# PCIE1_CORE_DBN_CFG_PCIE_CORE register map
Vendor: Texas Instruments
Registers are 32-bit, read-write, reset 0x0 unless marked. A register's access mark holds for its fields unless they carry their own. Offsets are as the file gives them; [hi:lo] are bit positions; {n}, {i} and the like mark numbered series; 'fields as' and 'values as' point back to an identical list.

## PCIE1_CORE_DBN_CFG_PCIE_CORE (part 6 of 7)
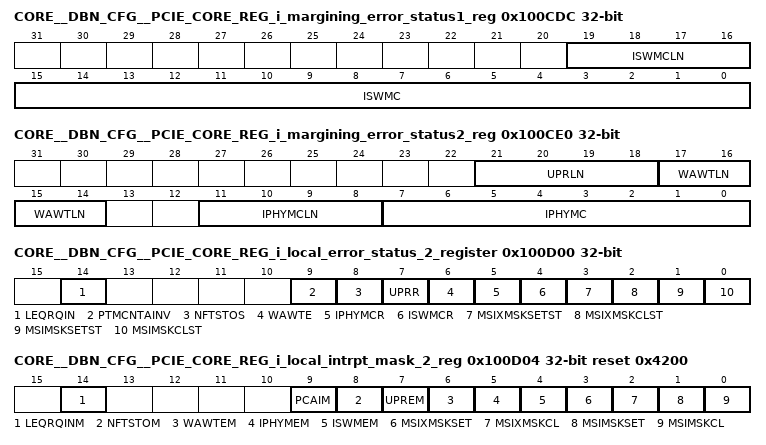
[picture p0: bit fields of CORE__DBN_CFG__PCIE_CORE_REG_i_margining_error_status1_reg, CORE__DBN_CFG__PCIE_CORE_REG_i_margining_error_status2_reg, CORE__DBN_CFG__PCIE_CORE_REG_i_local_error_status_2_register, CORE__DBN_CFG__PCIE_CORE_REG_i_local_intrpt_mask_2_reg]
0x100CDC CORE__DBN_CFG__PCIE_CORE_REG_i_margining_error_status1_reg ro — The Lane Margining at Receiver SW Error Status fields are implemented in this Register.
  [19:16] ISWMCLN — This field reports the Lane Number for which the Invalid command was received. 0000: Lane 0. 0001: Lane 1. and so on.. This register is valid only when Bit-4, Invalid SW Margining Command Received, of the i_local_error_status_2_register is set. Bit-4 of the i_local_error_status_2_register has to be cleared by local firmware before another error can be logged in this field. .
  [15:0] ISWMC — When the Controller receives an Invalid Margining Command from SW in its configuration register, the 16-bit command is logged in this register for debug. Only the first Error is logged in this register. This register is valid only when Bit-4, Invalid SW Margining Command Received, of the i_local_error_status_2_register is set. Bit-4 of the i_local_error_status_2_register has to be cleared by local firmware before another error can be logged in this field. .
0x100CE0 CORE__DBN_CFG__PCIE_CORE_REG_i_margining_error_status2_reg ro — The Lane Margining at Receiver PHY Error Status fields are implemented in this Register.
  [21:18] UPRLN — This field reports the Lane Number for which the Controller received an unexpected PHY Response for Lane Margining. Unexpected PHY Response is detected by Controller if PHY writes to the Margin Status or the Margin NAK bits of RX Margin Status 0 Register when no change in Start Margin or Margin Offset issued by Controller or after the Write Ack Wait Timeout. 0000: Lane 0. 0001: Lane 1. and so on.. This field is valid only when Bit-7, Unexpected PHY Response Received, of the i_local_error_status_2_register is set. Bit-7 of the i_local_error_status_2_register has to be cleared by local firmware before another error can be logged in this field. .
  [17:14] WAWTLN — This field reports the Lane Number for which the Controller detected a 10ms timeout. 0000: Lane 0. 0001: Lane 1. and so on.. This field is valid only when Bit-6, Write Ack Wait Timeout Error, of the i_local_error_status_2_register is set. Bit-6 of the i_local_error_status_2_register has to be cleared by local firmware before another error can be logged in this field. .
  [11:8] IPHYMCLN — This field reports the Lane Number for which the Invalid command was received. 0000: Lane 0. 0001: Lane 1. and so on.. This field is valid only when Bit-5, Invalid PHY Margining Command Received, of the i_local_error_status_2_register is set. Bit-5 of the i_local_error_status_2_register has to be cleared by local firmware before another error can be logged in this field. .
  [7:0] IPHYMC — When the Controller receives an Invalid Margining Command from PHY over PIPE Interface, the 8-bit PIPE command is logged in this register for debug. Only the first Error is logged in this register. This field is valid only when Bit-5, Invalid PHY Margining Command Received, of the i_local_error_status_2_register is set. Bit-5 of the i_local_error_status_2_register has to be cleared by local firmware before another error can be logged in this field. .
0x100D00 CORE__DBN_CFG__PCIE_CORE_REG_i_local_error_status_2_register access not given — This is an extension of the Local Error and Status Register. This register contains the status of the various events, errors and abnormal conditions in the Controller. Any of the status bits can be reset by writing a 1 into the bit position. Unless masked by the setting of the Local Interrupt Mask 2 Register, the occurrence of any of these conditions causes the Controller to activate the LOCAL_INTERRUPT output.
  [14] LEQRQIN — EP Mode: Indicates that the Controller hardware detected a problem with equalization and automatically requested for equalization redo at the end of the equalization. Controller checks for problems in Recovery.Rcvr.Lock state by comparing the Tx Coefficients agreed at end of Eq Phase2 with the Tx Coefficients received in TS1s in Recovery.Rcvr.Lock state at the end of equalization. Any mismatch is detected and the Request Equalization bit is set in Recovery.Rcvg.Cfg. This bit is set for both 8GT/s and 16GT/s equalization requests. [i] The Link Eq Request 8GT/s bit-5 in Link Status 2 Register will be set for 8GT/s Eq Request. [ii] The Link Eq Request 16.0 GT/s, bit-4 in 16.0 GT/s Status Register will be set for 16GT/s Eq Request. RC Mode: Indicates that the Controller received Equalization Request from downstream component. This bit is set for both 8GT/s and 16GT/s equalization requests. [i] The Link Eq Request 8GT/s bit-5 in Link Status 2 Register will be set for 8GT/s Eq Request. [ii] The Link Eq Request 16.0 GT/s, bit-4 in 16.0 GT/s Status Register will be set for 16GT/s Eq Request. (access R/W1TC)
  [9] PTMCNTAINV — This status bit indicates that the Controller automatically invalidated PTM Context because of PCIe Link exit from L0 State. (access R/W1TC)
  [8] NFTSTOS — This status bit indicates that a NFTS Timeout occured. This could occur if the PHY failed to achieve lock on the receive data before the NFTS Timeout during Rx_L0s.FTS state. Local Firmware should consider increasing the advertized NFTS values if this event occurs. (access R/W1TC)
  [7] UPRR — This bit indicates that the Controller received an unexpected PHY Response for Lane Margining. The lane on which this error was detected is captured in bits 21:18 of the margining_error_status2_reg register. Unexpected PHY Response is detected by Controller if PHY writes to the Margin Status or the Margin NAK bits of the MAC RX Margin Status 0 Register when no change in Start Margin or Margin Offset issued by Controller or after the Write Ack Wait Timeout. This bit is set upon receiving the first Error. Local firmware must clear this bit by writing a 1 to this bit before another error can be logged in the margining_error_status2_reg register. (access R/W1TC)
  [6] WAWTE — This bit indicates that the Controller detected a 10ms timeout while waiting for Write Ack Lane Margining response from a PHY. The lane on which this timeout was detected is captured in bits 17:14 of the margining_error_status2_reg register. This bit is set upon receiving the first Error. Local firmware must clear this bit by writing a 1 to this bit before another error can be logged in the margining_error_status2_reg register. (access R/W1TC)
  [5] IPHYMCR — This bit validates the 8-bit command stored in bits [7:0] and the Lane Number stored in bits [11:8] of the margining_error_status1_reg register. This bit is set upon receiving the first Error. Local firmware must clear this bit by writing a 1 to this bit before another error can be logged in the margining_error_status1_reg register. (access R/W1TC)
  [4] ISWMCR — This bit validates the 16-bit command stored in bits [15:0] and the Lane Number stored in bits [19:16] of the margining_error_status1_reg register. This bit is set upon receiving the first Error. Local firmware must clear this bit by writing a 1 to this bit before another error can be logged in the margining_error_status1_reg register. (access R/W1TC)
  [3] MSIXMSKSETST — This status bit indicates that the MSIX Function Mask of any function, PF or VF, was programmed or configured from 0 to 1 by Local Firmware Or Host SW. This bit is set only when the MSIX Function Mask Change Enhanced Interrupt Enable bit is set by the User in debug_mux_control_2_reg. When this status bit is set, the Controller asserts LOCAL_INTERRUPT if not masked in local_intrpt_mask_2_reg . Note that this is a Read Only Status bit. The MSIX Function Mask Clear status per-function is captured in the msix_function_mask_set_status_register. Firmware has to clear the per-function bits in msix_function_mask_set_status_register in order to clear this status bit and to deassert LOCAL_INTERRUPT. (access R/W1TC)
  [2] MSIXMSKCLST — This status bit indicates that the MSIX Function Mask of any function, PF or VF, was programmed or configured from 1 to 0 by Local Firmware Or Host SW. This bit is set only when the MSIX Function Mask Change Enhanced Interrupt Enable bit is set by the User in debug_mux_control_2_reg. When this status bit is set, the Controller asserts LOCAL_INTERRUPT if not masked in local_intrpt_mask_2_reg . Note that this is a Read Only Status bit. The MSIX Function Mask Clear status per-function is captured in the msix_function_mask_cleared_status_register. Firmware has to clear the per-function bits in msix_function_mask_cleared_status_register in order to clear this status bit and to deassert LOCAL_INTERRUPT. (access R/W1TC)
  [1] MSIMSKSETST — This status bit indicates that One or More bits of MSI Mask of any function, PF or VF, was programmed or configured from 0 to 1 by Local Firmware Or Host SW. This bit is set only when the MSI Mask Change Enhanced Interrupt Enable bit is set by the User in debug_mux_control_2_reg. When this status bit is set, the Controller asserts LOCAL_INTERRUPT if not masked in local_intrpt_mask_2_reg . Note that this is a Read Only Status bit. The MSI Mask Clear status per-function is captured in the msi_mask_set_status_register. Firmware has to clear the per-function bits in msi_mask_set_status_register in order to clear this status bit and to deassert LOCAL_INTERRUPT. (access R/W1TC)
  [0] MSIMSKCLST — This status bit indicates that One or More bits of MSI Mask of any function, PF or VF, was programmed or configured from 1 to 0 by Local Firmware Or Host SW. This bit is set only when the MSI Mask Change Enhanced Interrupt Enable bit is set by the User in debug_mux_control_2_reg. When this status bit is set, the Controller asserts LOCAL_INTERRUPT if not masked in local_intrpt_mask_2_reg . Note that this is a Read Only Status bit. The MSI Mask Clear status per-function is captured in the msi_mask_cleared_status_register. Firmware has to clear the per-function bits in msi_mask_cleared_status_register in order to clear this status bit and to deassert LOCAL_INTERRUPT. (access R/W1TC)
0x100D04 CORE__DBN_CFG__PCIE_CORE_REG_i_local_intrpt_mask_2_reg reset 0x4200 — This is an extension of the Local Interrupt Mask Register. This register contains a mask bit for each interrupting condition in local_error_status_2_register. Setting the bit to 1 prevents the corresponding condition in the Local Error Status 2 Register from activating the LOCAL_INTERRUPT output.
  [14] LEQRQINM — Mask for Link Equalization Request Interrupt.
  [9] PCAIM — Mask for PTM Context Auto Invalidated event.
  [8] NFTSTOM — Mask for NFTS Timeout.
  [7] UPREM — Unexpected PHY Response is detected by Controller if PHY writes to the Margin Status or the Margin NAK bits of RX Margin Status 0 Register when no change in Start Margin or Margin Offset issued by Controller or after the Write Ack Wait Timeout This bit can be used to Mask asserting the LOCAL_INTERRUPT output upon this error. 1: Error is masked. 0: Error is not masked.
  [6] WAWTEM — When a WriteCommitted command is issued by the Controller, the PHY must respond with a Write_Ack within 10ms on the PIPE Message Bus Interface. However, if the Write_Ack is not received within 10ms, the Controller reports Timeout and stops waiting for the write_ack. This bit can be used to Mask asserting the LOCAL_INTERRUPT output upon this 10ms timeout. 1: Error is masked. 0: Error is not masked.
  [5] IPHYMEM — When the Controller receives a Margining Command from PHY over the PIPE Interface, it checks if the command is valid. The error status is logged in local_error_status_2_register. This bit can be used to Mask asserting the LOCAL_INTERRUPT output when the Invalid PHY Margining Error Status is set. 1: Error is masked. 0: Error is not masked.
  [4] ISWMEM — When the Controller receives a Margining Command from SW in its configuration register, it checks if the command is valid. The error status is logged in local_error_status_2_register. This bit can be used to Mask asserting the LOCAL_INTERRUPT output when the Invalid SW Margining Error Status is set. 1: Error is masked. 0: Error is not masked. .
  [3] MSIXMSKSET — Mask for MSIX Function Mask Cleared Status.
  [2] MSIXMSKCL — Mask for MSIX Function Mask Set Status.
  [1] MSIMSKSET — Mask for MSI Mask Set Status.
  [0] MSIMSKCL — Mask for MSI Mask Cleared Status.
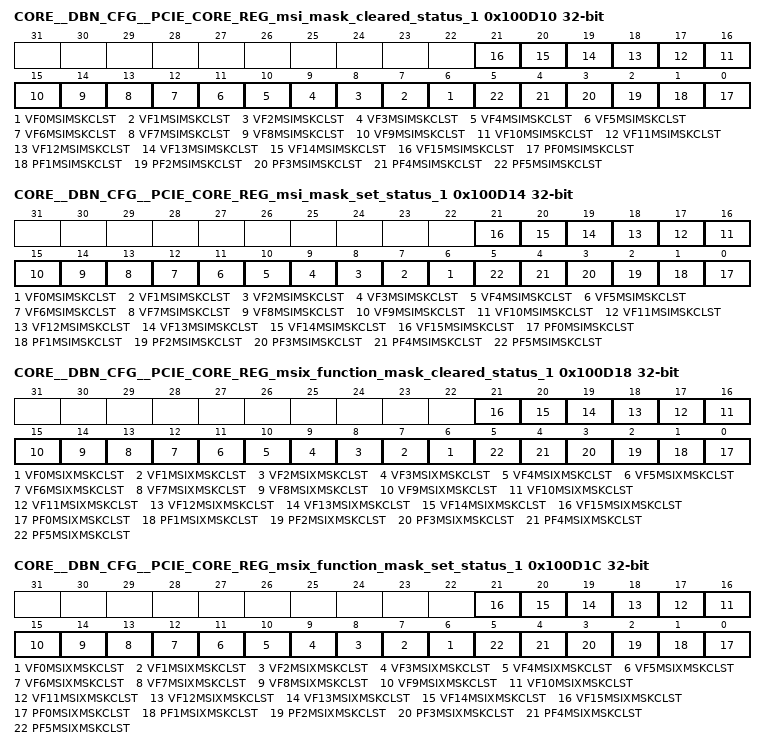
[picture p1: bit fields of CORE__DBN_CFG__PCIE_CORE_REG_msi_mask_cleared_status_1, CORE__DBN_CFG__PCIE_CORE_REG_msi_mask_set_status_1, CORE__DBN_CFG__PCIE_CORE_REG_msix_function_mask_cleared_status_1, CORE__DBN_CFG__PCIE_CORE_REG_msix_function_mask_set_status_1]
0x100D10 CORE__DBN_CFG__PCIE_CORE_REG_msi_mask_cleared_status_1 access not given — This status register has one bit per function. Each function has a 32-bit MSI Mask. If any bit in the function's MSI Mask register is configured from 1 to 0, then the corresponding function's status bit in this register is set. Local Firmware needs to clear this register by writing a 1.
  [n+6] VF{n}MSIMSKCLST (n=0..15) — Each VF has a 32-bit MSI Mask. This status bit is set when any of the 32-bits in VF{n} MSI Mask is programmed or configured from 1 to 0 by Local Firmware Or Host SW. This bit is set only when the MSI Mask Change Enhanced Interrupt Enable bit is set by the User in debug_mux_control_2_reg. When this status bit is set, the Controller asserts LOCAL_INTERRUPT if not masked in local_intrpt_mask_2_reg . Firmware has to clear this bit in order to deassert LOCAL_INTERRUPT. (access R/W1TC)
  [n] PF{n}MSIMSKCLST (n=0..5) — Each PF has a 32-bit MSI Mask. This status bit is set when any of the 32-bits in PF{n} MSI Mask is programmed or configured from 1 to 0 by Local Firmware Or Host SW. This bit is set only when the MSI Mask Change Enhanced Interrupt Enable bit is set by the User in debug_mux_control_2_reg. When this status bit is set, the Controller asserts LOCAL_INTERRUPT if not masked in local_intrpt_mask_2_reg . Firmware has to clear this bit in order to deassert LOCAL_INTERRUPT. (access R/W1TC)
0x100D14 CORE__DBN_CFG__PCIE_CORE_REG_msi_mask_set_status_1 access not given — This status register has one bit per function. Each function has a 32-bit MSI Mask. If any bit in the function's MSI Mask register is configured from 0 to 1, then the corresponding function's status bit in this register is set. Local Firmware needs to clear this register by writing a 1.
  [n+6] VF{n}MSIMSKCLST (n=0..15) — Each VF has a 32-bit MSI Mask. This status bit is set when any of the 32-bits in VF{n} MSI Mask is programmed or configured from 0 to 1 by Local Firmware Or Host SW. This bit is set only when the MSI Mask Change Enhanced Interrupt Enable bit is set by the User in debug_mux_control_2_reg. When this status bit is set, the Controller asserts LOCAL_INTERRUPT if not masked in local_intrpt_mask_2_reg . Firmware has to clear this bit in order to deassert LOCAL_INTERRUPT. (access R/W1TC)
  [n] PF{n}MSIMSKCLST (n=0..5) — Each PF has a 32-bit MSI Mask. This status bit is set when any of the 32-bits in PF{n} MSI Mask is programmed or configured from 0 to 1 by Local Firmware Or Host SW. This bit is set only when the MSI Mask Change Enhanced Interrupt Enable bit is set by the User in debug_mux_control_2_reg. When this status bit is set, the Controller asserts LOCAL_INTERRUPT if not masked in local_intrpt_mask_2_reg . Firmware has to clear this bit in order to deassert LOCAL_INTERRUPT. (access R/W1TC)
0x100D18 CORE__DBN_CFG__PCIE_CORE_REG_msix_function_mask_cleared_status_1 access not given — This status register has one bit per function. Each function has a 1-bit MSIX Function Mask. If the function's MSIX Function Mask register is configured from 1 to 0, then the corresponding function's status bit in this register is set. Local Firmware needs to clear this register by writing a 1.
  [n+6] VF{n}MSIXMSKCLST (n=0..15) — Each VF has a 1-bit MSIX Function Mask. This status bit is set when the VF{n} MSIX Function Mask is programmed or configured from 1 to 0 by Local Firmware Or Host SW. This bit is set only when the MSIX Function Mask Change Enhanced Interrupt Enable bit is set by the User in debug_mux_control_2_reg. When this status bit is set, the Controller asserts LOCAL_INTERRUPT if not masked in local_intrpt_mask_2_reg . Firmware has to clear this bit in order to deassert LOCAL_INTERRUPT. (access R/W1TC)
  [n] PF{n}MSIXMSKCLST (n=0..5) — Each PF has a 1-bit MSIX Function Mask. This status bit is set when the PF{n} MSIX Function Mask is programmed or configured from 1 to 0 by Local Firmware Or Host SW. This bit is set only when the MSIX Function Mask Change Enhanced Interrupt Enable bit is set by the User in debug_mux_control_2_reg. When this status bit is set, the Controller asserts LOCAL_INTERRUPT if not masked in local_intrpt_mask_2_reg . Firmware has to clear this bit in order to deassert LOCAL_INTERRUPT. (access R/W1TC)
0x100D1C CORE__DBN_CFG__PCIE_CORE_REG_msix_function_mask_set_status_1 access not given — This status register has one bit per function. Each function has a 1-bit MSIX Function Mask. If the function's MSIX Function Mask register is configured from 0 to 1, then the corresponding function's status bit in this register is set. Local Firmware needs to clear this register by writing a 1.
  [n+6] VF{n}MSIXMSKCLST (n=0..15) — Each VF has a 1-bit MSIX Function Mask. This status bit is set when the VF{n} MSIX Function Mask is programmed or configured from 0 to 1 by Local Firmware Or Host SW. This bit is set only when the MSIX Function Mask Change Enhanced Interrupt Enable bit is set by the User in debug_mux_control_2_reg. When this status bit is set, the Controller asserts LOCAL_INTERRUPT if not masked in local_intrpt_mask_2_reg . Firmware has to clear this bit in order to deassert LOCAL_INTERRUPT. (access R/W1TC)
  [n] PF{n}MSIXMSKCLST (n=0..5) — Each PF has a 1-bit MSIX Function Mask. This status bit is set when the PF{n} MSIX Function Mask is programmed or configured from 0 to 1 by Local Firmware Or Host SW. This bit is set only when the MSIX Function Mask Change Enhanced Interrupt Enable bit is set by the User in debug_mux_control_2_reg. When this status bit is set, the Controller asserts LOCAL_INTERRUPT if not masked in local_intrpt_mask_2_reg . Firmware has to clear this bit in order to deassert LOCAL_INTERRUPT. (access R/W1TC)
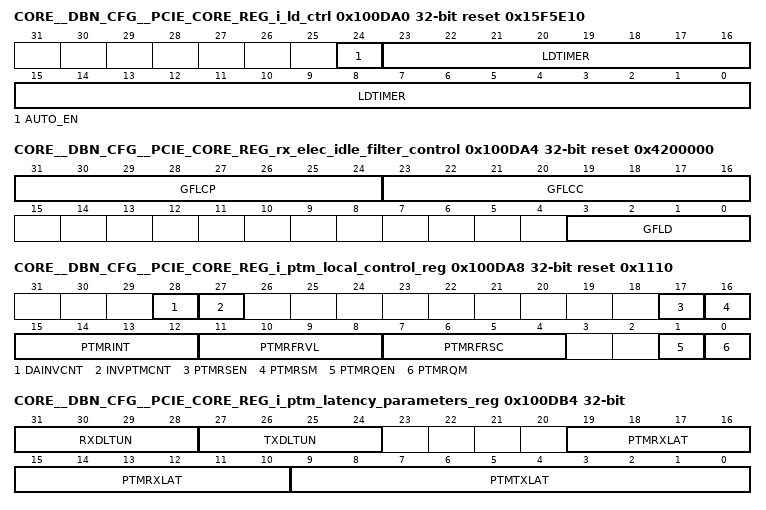
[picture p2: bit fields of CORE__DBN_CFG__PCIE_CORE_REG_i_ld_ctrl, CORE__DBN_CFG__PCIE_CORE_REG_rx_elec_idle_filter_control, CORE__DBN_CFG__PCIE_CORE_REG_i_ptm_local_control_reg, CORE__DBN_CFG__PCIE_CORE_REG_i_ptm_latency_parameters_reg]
0x100DA0 CORE__DBN_CFG__PCIE_CORE_REG_i_ld_ctrl reset 0x15F5E10 — This register is for the control of Link Down Indication Auto Reset behavior
  [24] AUTO_EN — This bit when set indicates that the link down indication auto reset is enabled
  [23:0] LDTIMER — This is a counter timeout value which triggers the internal logic to reset the link down indication bit in the AXI Configuration registers
0x100DA4 CORE__DBN_CFG__PCIE_CORE_REG_rx_elec_idle_filter_control reset 0x4200000 — This register controls the behavior of glitch filter on the pipe rx Electrical Idle signal from the PHY/PCS. Adjustment of this register is not required for normal operations.
  [31:24] GFLCP — This controls the glitch filter on PM Clock domain. This counter indicates the number of PM Clocks the glitch will be filtered out. The total delay of the glitch filter is calculated as [PM Clock Period * Number of PM Clocks] this delay should be same or close enough for both Core Clock[GFLCC] and PM Clock[GFLCP]
  [23:16] GFLCC — This controls the glitch filter on CORE Clock domain. This counter indicates the number of CORE Clocks the glitch will be filtered out. The total delay of the glitch filter is calculated as [CORE Clock Period * Number of CORE Clocks] this delay should be same or close enough for both CORE Clock[GFLCC] and PM Clock[GFLCP]
  [3:0] GFLD — By default controller enables glitch filter on all lanes. Setting this bit to one makes the controller to disable the glitch filter on that corresponding lanes in which the bit is set. When all bits are set to one the Glitch filter is completely bypassed, When any bit is zero glitch filter is enabled, and de-glitching is done only on the lanes that are set to zero
0x100DA8 CORE__DBN_CFG__PCIE_CORE_REG_i_ptm_local_control_reg access per field reset 0x1110 — The register bits to Control PTM operation are implemented in this Register.
  [28] DAINVCNT rw — By default, the Controller automatically invalidates PTM Context when the LTSSM exits L0 state. Client may disable this by writing a 1 to this register.
  [27] INVPTMCNT wo — Client Firmware may write a 1 to this bit in order to reset the PTM Context. This is a write-only bit. Controller internally clears this bit. Read from this bit returns 0. EP Mode: Resets the PTM Request State Machine. PTM Context is Cleared. RP Mode: Resets the PTM Response State Machine. PTM Context is Cleared.
  [17] PTMRSEN rw — EP Mode: Reserved RP Mode: This bit enables Controller [RP] to respond to the received PTM Requests. PTM Response/PTM ResponseD is determined by the PTM Response Mode bit. 1 : Controller automatically responds with Response/ResponseD messages. 0 : Controller does not respond for PTM Requests. [PTM Feature is Bypassed.]
  [16] PTMRSM rw — EP Mode: Reserved. RP Mode: This bit is used to control the number of PTM dialogs used during each PTM Master Time Request. 1 : Two Dialog Mode - Each PTM Context will have Response followed by ResponseD. Example: Dialog0: Request -> Response. Dialog1: Request -> ResponseD Dialog2: Request -> Response Dialog3: Request -> ResponseD 0 : Continuous Dialog Mode - Each PTM Context will have Only ResponseD. Example: Dialog0: Request -> Response. Dialog1: Request -> ResponseD Dialog2: Request -> ResponseD Dialog3: Request -> ResponseD
  [15:12] PTMRINT rw — EP Mode: In Single,Periodic Request Mode, this field is used to control the time interval [in us] between PTM Requests within a PTM Context. This represents the time the Requester State Machine waits in the WAIT_1US_STATE. 0001 - 1 0010 - 2 0011 - 3 0100 - 4 0101 - 5 0110 - 6 0111 - 7 1000 - 8 1001 - 9 .. 1111 - 15 This value is in [us]. RP Mode: Reserved.
  [11:8] PTMRFRVL rw — EP Mode: In Periodic Request Mode, this field is used to control the time interval [value] between successive PTM Context Refresh. This represents the time the Requester State Machine waits in the VALID_PTM_CONTEXT_STATE. 0001 - 1 0010 - 2 0011 - 3 0100 - 4 0101 - 5 0110 - 6 0111 - 7 1000 - 8 1001 - 9 1010 - 1111 Reserved This value is multiplied with the scale to determine the PTM Request Time Interval. RP Mode: Reserved.
  [7:4] PTMRFRSC rw — EP Mode: In Periodic Request Mode, this field is used to control the time interval [scale] between successive PTM Context Refresh. This represents the time the Requester State Machine waits in the VALID_PTM_CONTEXT_STATE. 0000 - 1 us 0001 - 10 us 0010 - 100 us 0011 - 1 ms 0100 - 10 ms 0101 - 100 ms 0110 - 1 s 0111 - 10 s 1000 - 100 s 1001 - 1111 - Reserved RP Mode: Reserved.
  [1] PTMRQEN rw — EP Mode: This enables Endpoint to request for PTM Master Time. 1 : PTM Requests are Enabled. In Single Request Mode, this bit is used to trigger PTM dialog to obtain PTM Master time exactly once. This bit is auto-cleared after the PTM Master time is obtained. In Periodic Request Mode, this bit enables periodic requests for PTM Master Time. This bit remains set till it is cleared by the EP local firmware. 0 : PTM Requests are Disabled. [PTM Feature is Bypassed.] User may disable PTM requests in the Controller and, if required, generate requests from Client Master Interface. RP Mode: Reserved.
  [0] PTMRQM rw — EP Mode: This bit controls the pattern of PTM Requests issued by the Endpoint. 0: Single Request Mode. 1: Periodic Request Mode. In Single Request Mode, Endpoint initiates one or two PTM Dialogs till the PTM Master Time is obtained. In Periodic Request Mode, Endpoint initiates PTM Dialogs and obtains PTM Master at periodic intervals. The period is programmable. RP Mode: Reserved.
0x100DAC CORE__DBN_CFG__PCIE_CORE_REG_i_ptm_local_status_reg ro — The status of PTM Dialog is reflected in this Register.
  [3:0] PTMCNST — Reflects the current status of the PTM Context. In EP Mode: 0000 - Invalid PTM Context 0001 - Dialog 1 PTM Request Sent 0011 - Dialog 1 PTM Response Received 0111 - Dialog 2 PTM Request Sent 1111 - Dialog 2 PTM ResponseD Received and PTM Context Valid In RP Mode: 0000 - Invalid PTM Context 0001 - Dialog 1 PTM Request Received 0011 - Dialog 1 PTM Response Sent 0111 - Dialog 2 PTM Request Received 1111 - Dialog 2 PTM ResponseD Sent and PTM Context Valid
0x100DB0 CORE__DBN_CFG__PCIE_CORE_REG_i_ptm_latency_parameters_index_reg — The latency parameters of the PHY may be different at different speeds of operation. Hence, the Controller implements multiple instances of the PTM Latency Parameters Register, one instance for each speed of operation. This register is used to select the speed prior to programming the speed-specific delay parameter registers.
  [3:0] PTMLATIN — This is used by FW to select the speed for which the Latency parameters are to be programmed. FW is required to set this to each of the supported speeds and program the corresponding latency parameters in the PTM Latency Parameters Register. 0000 - Gen1 Speed Select 0001 - Gen2 Speed Select 0010 - Gen3 Speed Select 0011 - Gen4 Speed Select Others - Reserved
0x100DB4 CORE__DBN_CFG__PCIE_CORE_REG_i_ptm_latency_parameters_reg — This register is used to define the PHY specific delay parameters. This register also implements control bits to fine-tune timestamps that are captured by the Controller. Internally, one instance of this register is implemented for each of the speeds supported by the Controller and is indexed by the PTM Latency Parameters Index Register.
  [31:28] RXDLTUN — In EP Mode: This field can be used to add a fixed offset to the captured timestamps t4 and t4_tick. In RP Mode: This field can be used to add a fixed offset to the captured timestamps t2 and t2_tick. Encoding: 0000: + 0 ns 0001: + 1ns 0010: + 2ns .... 1111: + 15ns Separate value can be programmed for each supported speed of operation. The speed of operation must first be programmed in the PTM Latency Parameters Index Register and then the corresponding value be programmed into this register.
  [27:24] TXDLTUN — In EP Mode: This field can be used to add a fixed offset to the captured timestamps t1 and t1_tick. In RP Mode: This field can be used to add a fixed offset to the captured timestamps t3 and t3_tick. Encoding: 0000: + 0 ns 0001: + 1ns 0010: + 2ns .... 1111: + 15ns Separate value can be programmed for each supported speed of operation. The speed of operation must first be programmed in the PTM Latency Parameters Index Register and then the corresponding value be programmed into this register.
  [19:10] PTMRXLAT — This field should be programmed with the parameter Receive Latency in [ns] from the PHY Datasheet. Separate value can be programmed for each supported speed of operation. The speed of operation must first be programmed in the PTM Latency Parameters Index Register and then the corresponding latency be programmed into this register.
  [9:0] PTMTXLAT — This field should be programmed with the parameter Transmit Latency in [ns] from the PHY Datasheet. Separate value can be programmed for each supported speed of operation. The speed of operation must first be programmed in the PTM Latency Parameters Index Register and then the corresponding latency be programmed into this register.
0x100DB8 CORE__DBN_CFG__PCIE_CORE_REG_i_ptm_context_1_reg ro — PTM Context 1 Register.
  [31:0] PTMT1T2 — EP Mode : Represents the lower 32-bits of timestamp t1 in [ns] as recorded by Endpoint. RP Mode : Represents the lower 32-bits of timestamp t2 in [ns] as recorded by RP.
0x100DBC CORE__DBN_CFG__PCIE_CORE_REG_i_ptm_context_2_reg ro — PTM Context 2 Register.
  [31:0] PTMT1T2U — EP Mode : Represents the upper 32-bits of timestamp t1 in [ns] as recorded by Endpoint. RP Mode : Represents the upper 32-bits of timestamp t2 in [ns] as recorded by RP.
0x100DC0 CORE__DBN_CFG__PCIE_CORE_REG_i_ptm_context_3_reg ro — PTM Context 3 Register.
  [31:0] PTMT4T3 — EP Mode : Represents the lower 32-bits of timestamp t4 in [ns] as recorded by Endpoint. RP Mode : Represents the lower 32-bits of timestamp t3 in [ns] as recorded by RP.
0x100DC4 CORE__DBN_CFG__PCIE_CORE_REG_i_ptm_context_4_reg ro — PTM Context 4 Register.
  [31:0] PTMT4T3U — EP Mode : Represents the upper 32-bits of timestamp t4 in [ns] as recorded by Endpoint. RP Mode : Represents the upper 32-bits of timestamp t3 in [ns] as recorded by RP.
0x100DC8 CORE__DBN_CFG__PCIE_CORE_REG_i_ptm_context_5_reg ro — PTM Context 5 Register.
  [31:0] PTMT1KT2K — EP Mode : Represents the lower 32-bits of timestamp t1_tick in [ns] as recorded by Endpoint. RP Mode : Represents the lower 32-bits of timestamp t2_tick in [ns] as recorded by RP.
0x100DCC CORE__DBN_CFG__PCIE_CORE_REG_i_ptm_context_6_reg ro — PTM Context 6 Register.
  [31:0] PTMT1KT2KU — EP Mode : Represents the upper 32-bits of timestamp t1_tick in [ns] as recorded by Endpoint. RP Mode : Represents the upper 32-bits of timestamp t2_tick in [ns] as recorded by RP.
0x100DD0 CORE__DBN_CFG__PCIE_CORE_REG_i_ptm_context_7_reg ro — PTM Context 7 Register.
  [31:0] PTMT4KT3K — EP Mode : Represents the lower 32-bits of timestamp t4_tick in [ns] as recorded by Endpoint. RP Mode : Represents the lower 32-bits of timestamp t3_tick in [ns] as recorded by RP.
0x100DD4 CORE__DBN_CFG__PCIE_CORE_REG_i_ptm_context_8_reg ro — PTM Context 8 Register.
  [31:0] PTMT4KT3KU — EP Mode : Represents the upper 32-bits of timestamp t4_tick in [ns] as recorded by Endpoint. RP Mode : Represents the upper 32-bits of timestamp t3_tick in [ns] as recorded by RP.
0x100DD8 CORE__DBN_CFG__PCIE_CORE_REG_i_ptm_context_9_reg ro — PTM Context 9 Register.
  [31:0] PTMT3MT2 — Propagation Delay. EP Mode : Represents the Propagation Delay [t3 - t2] in [ns] as received in ResponseD Message by Endpoint. RP Mode - Reserved.
0x100DDC CORE__DBN_CFG__PCIE_CORE_REG_i_ptm_context_10_reg ro — PTM Context 10 Register.
  [31:0] PTMMSTT1T — EP Mode - Represents the lower 32-bits of PTM Master Time at timestamp t1_tick in [ns] as computed by Endpoint. RP Mode - Reserved.
0x100DE0 CORE__DBN_CFG__PCIE_CORE_REG_i_ptm_context_11_reg ro — PTM Context 11 Register.
  [31:0] PTMMSTT1TU — EP Mode - Represents the upper 32-bits of PTM Master Time at timestamp t1_tick in [ns] as computed by Endpoint. RP Mode - Reserved.
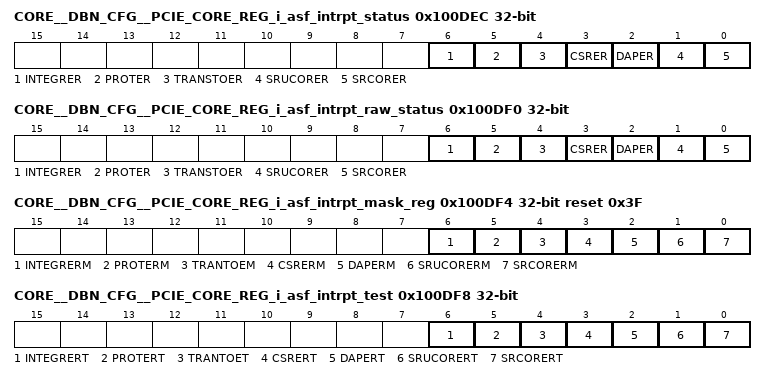
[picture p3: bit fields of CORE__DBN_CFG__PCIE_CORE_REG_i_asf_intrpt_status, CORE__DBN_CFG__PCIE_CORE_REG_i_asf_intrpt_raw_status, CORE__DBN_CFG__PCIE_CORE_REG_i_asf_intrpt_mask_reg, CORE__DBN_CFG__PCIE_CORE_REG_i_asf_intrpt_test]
0x100DEC CORE__DBN_CFG__PCIE_CORE_REG_i_asf_intrpt_status access not given — This register indicates the source of ASF interrupts. The corresponding bit in the mask register must be clear for a bit to be set. If any bit is set in this register the asf_fatal or asf_nonfatal signal will be asserted. Writing to either raw or masked status registers, clear both registers. For test purposes, trigger signal interrupt event by writing to the ASF interrupt status test register.
  [6] INTEGRER — Integrity error interrupt (access R/W1TC)
  [5] PROTER — Protocol error interrupt (access R/W1TC)
  [4] TRANSTOER — Transaction timeouts interrupt (access R/W1TC)
  [3] CSRER — Configuration and status registers error interrupt (access R/W1TC)
  [2] DAPER — Data and address paths error interrupt (access R/W1TC)
  [1] SRUCORER — SRAM Uncorrectable error interrupt (access R/W1TC)
  [0] SRCORER — SRAM Correctable error interrupt (access R/W1TC)
0x100DF0 CORE__DBN_CFG__PCIE_CORE_REG_i_asf_intrpt_raw_status access not given — A bit set in this raw register indicates a source of ASF fault in the corresponding feature. Writing to either raw or masked status registers, clear both registers. For test purposes, trigger signal interrupt event by writing to the ASF interrrupt status test register.
  fields as CORE__DBN_CFG__PCIE_CORE_REG_i_asf_intrpt_status
0x100DF4 CORE__DBN_CFG__PCIE_CORE_REG_i_asf_intrpt_mask_reg reset 0x3F — This Register indicates which interrupt bits in the ASF interrupt status register are masked. Setting the individual bit to zero would enable the corresponding interrupt. This register does not affect the raw interrupt status register
  [6] INTEGRERM — Mask bit for Integrity error interrupt
  [5] PROTERM — Mask bit for Protocol error interrupt
  [4] TRANTOEM — Mask bit for Transaction timeouts interrupt
  [3] CSRERM — Mask bit for Configuration and status registers error interrupt
  [2] DAPERM — Mask bit for Data and address paths error interrupt
  [1] SRUCORERM — Mask bit for SRAM Uncorrectable error interrupt
  [0] SRCORERM — Mask bit for SRAM Correctable error interrupt
0x100DF8 CORE__DBN_CFG__PCIE_CORE_REG_i_asf_intrpt_test wo — Writing one to individual bits will trigger corresponding interrupt event. The raw interrupt status will be set and the masked interrupt status will be set if the corresponding bit in the interrupt mask register is not set.
  [6] INTEGRERT — Test bit for Integrity error interrupt
  [5] PROTERT — Test bit for Protocol error interrupt
  [4] TRANTOET — Test bit for Transaction timeouts interrupt
  [3] CSRERT — Test bit for Configuration and status registers error interrupt
  [2] DAPERT — Test bit for Data and address paths error interrupt
  [1] SRUCORERT — Test bit for SRAM Uncorrectable error interrupt
  [0] SRCORERT — Test bit for SRAM Correctable error interrupt
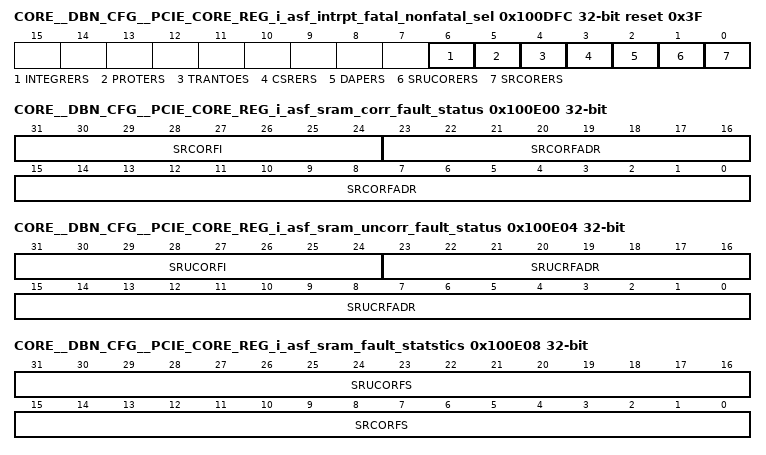
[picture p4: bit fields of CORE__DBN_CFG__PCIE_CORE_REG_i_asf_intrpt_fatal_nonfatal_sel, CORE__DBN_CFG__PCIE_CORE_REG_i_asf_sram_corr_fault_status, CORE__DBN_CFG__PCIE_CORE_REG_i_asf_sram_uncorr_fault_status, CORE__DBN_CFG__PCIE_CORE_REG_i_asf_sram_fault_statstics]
0x100DFC CORE__DBN_CFG__PCIE_CORE_REG_i_asf_intrpt_fatal_nonfatal_sel reset 0x3F — This register selects whether a fatal (asf_int_fatal) or non-fatal (asf_int_nonfatal) interrupt is triggered. For each select bit, if it is set to one then a fatal interrupt (asf_int_fatal) will be triggered. Otherwise the non-fatal interrupt (asf_int_nonfatal) will be triggered. For either a Fatal or Non Fatal Interrupt to be triggered , the corresponding mask bit of the error needs to be zero.
  [6] INTEGRERS — Enable Integrity error as Fatal
  [5] PROTERS — Enable protocol interrupt as fatal
  [4] TRANTOES — Enable transaction timeouts interrupt as fatal
  [3] CSRERS — Enable configuration and status registers interrupt as fatal
  [2] DAPERS — Enable data and address paths interrupt as fatal
  [1] SRUCORERS — Enable SRAM Uncorrectable interrupt as fatal
  [0] SRCORERS — Enable SRAM correctable interrupt as fatal
0x100E00 CORE__DBN_CFG__PCIE_CORE_REG_i_asf_sram_corr_fault_status ro — These fields are updated whenever asf_sram_corr_fault input is active
  [31:24] SRCORFI — This ENCODING indicates which SRAM Instance has a Correctable Fault. The Encoding of the SRAM is listed under Section: IP Embedded SRAM Protection in Table: SRAM Instance EnCoding
  [23:0] SRCORFADR — This indicates the address where the Correctable fault was observed.
0x100E04 CORE__DBN_CFG__PCIE_CORE_REG_i_asf_sram_uncorr_fault_status ro — These fields are updated whenever asf_sram_uncorr_fault input is active
  [31:24] SRUCORFI — This ENCODING indicates which SRAM Instance has a Uncorrectable Fault. The Encoding of the SRAM is shown in Table 26
  [23:0] SRUCRFADR — This indicates the address where the Uncorrectable fault was observed.
0x100E08 CORE__DBN_CFG__PCIE_CORE_REG_i_asf_sram_fault_statstics access not given — Note that this register clears when software writes to any field
  [31:16] SRUCORFS — Counts the number of SRAM Uncorrectable errors seen. (access R/W1TC)
  [15:0] SRCORFS — Counts the number of SRAM Correctable errors seen. (access R/W1TC)
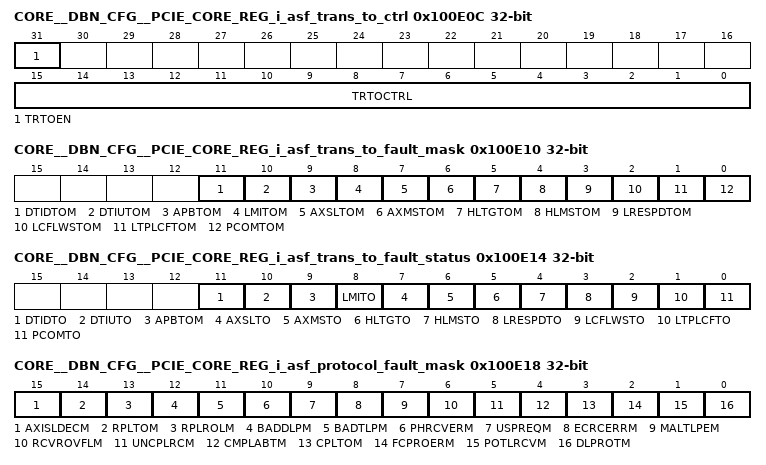
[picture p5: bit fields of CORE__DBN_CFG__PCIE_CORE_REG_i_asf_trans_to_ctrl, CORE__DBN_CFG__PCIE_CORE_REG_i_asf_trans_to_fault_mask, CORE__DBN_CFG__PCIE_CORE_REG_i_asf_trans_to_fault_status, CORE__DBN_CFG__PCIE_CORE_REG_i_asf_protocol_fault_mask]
0x100E0C CORE__DBN_CFG__PCIE_CORE_REG_i_asf_trans_to_ctrl — Register to program Transaction timeout in monitor and enable it
  [31] TRTOEN — Enable transaction timeout monitoring.
  [15:0] TRTOCTRL — Timer value to use for transaction timeout monitor.This is counted in resolution of 1 ms.
0x100E10 CORE__DBN_CFG__PCIE_CORE_REG_i_asf_trans_to_fault_mask — Disables the Timeout Completion Reporting
  [11] DTIDTOM — When written to 1 Disables DTI DN I/F timeout Reporting Error status reporting
  [10] DTIUTOM — When written to 1 Disables DTI UP I/F timeout Reporting Error status reporting
  [9] APBTOM — When written to 1 Disables APB I/F timeout Error status reporting
  [8] LMITOM — When written to 1 Disables Local Management I/F timeout Error status reporting
  [7] AXSLTOM — When written to 1 Disables AXI Slave I/F timeout Error status reporting
  [6] AXMSTOM — When written to 1 Disables AXI Target I/F timeout Error status reporting
  [5] HLTGTOM — When written to 1 Disables HAL Target I/F timeout Error status reporting
  [4] HLMSTOM — When written to 1 Disables HAL Master I/F timeout Error status reporting
  [3] LRESPDTOM — When written to 1 Disables LTSSM Recovery Speed Timeout Error status reporting
  [2] LCFLWSTOM — When written to 1 Disables LTSSM Cfg Link Width Start Timeout Error status reporting
  [1] LTPLCFTOM — When written to 1 Disables LTSSM Polling Configuration Timeout Error status reporting
  [0] PCOMTOM — When written to 1 Disables PCIe Completion Timeout Error status reporting
0x100E14 CORE__DBN_CFG__PCIE_CORE_REG_i_asf_trans_to_fault_status access not given — If a fault occurs the relevant status bit will be set to 1. Each bit can be cleared by software writing 1 to each bit
  [11] DTIDTO — DTI DN I/F Timeout detected waiting for a response from User (access R/W1TC)
  [10] DTIUTO — DTI UP I/F Timeout detected waiting for a response from User (access R/W1TC)
  [9] APBTOM — APB I/F Timeout detected waiting for a response from User (access R/W1TC)
  [8] LMITO — Local Management I/F Timeout detected waiting for a response from User (access R/W1TC)
  [7] AXSLTO — AXI Slave I/F Timeout detected waiting for a response (access R/W1TC)
  [6] AXMSTO — AXI Master I/F Timeout detected waiting for a response (access R/W1TC)
  [5] HLTGTO — HAL Target I/F Timeout detected waiting for a response (access R/W1TC)
  [4] HLMSTO — HAL Master I/F Timeout detected waiting for a response (access R/W1TC)
  [3] LRESPDTO — This Indicates if the states of the LTSSM timed out . 48 ms timeout in Rec.Speed-> Detect (access R/W1TC)
  [2] LCFLWSTO — This Indicates if the states of the LTSSM timed out . 24 ms Timeout observed in Cfg.Link.Width.Start -> Detect (access R/W1TC)
  [1] LTPLCFTO — This Indicates if the states of the LTSSM timed out . 48 ms Timeout observed for Polling.Cfg-> Detect (access R/W1TC)
  [0] PCOMTO — This indicates if a Non Posted requested did NOT receive any competition from remote device with in the completion time specified (access R/W1TC)
0x100E18 CORE__DBN_CFG__PCIE_CORE_REG_i_asf_protocol_fault_mask — This control register controls if a particular protocol error is disabled from being used in the generation of the ASF Protocol Error.
  [15] AXISLDECM — When set to 1 disables the AXI Slave/Decode Error status reporting
  [14] RPLTOM — When set to 1 disables the Replay Timer Timeout status reporting
  [13] RPLROLM — When set to 1 disables the Replay Number Rollover Detected status reporting
  [12] BADDLPM — When set to 1 disables the Bad DLLP Detected status reporting
  [11] BADTLPM — When set to 1 disables the Bad TLP Detected status reporting
  [10] PHRCVERM — When set to 1 disables the PHY Receiver Error Detected status reporting
  [9] USPREQM — When set to 1 disables the Unsupported Request Error status reporting
  [8] ECRCERRM — When set to 1 disables the ECRC Error Detected status reporting
  [7] MALTLPEM — When set to 1 disables the Malformed Error status reporting
  [6] RCVROVFLM — When set to 1 disables the Receiver Overflow Error status reporting
  [5] UNCPLRCM — When set to 1 disables the Unexpcted Completion status reporting
  [4] CMPLABTM — When set to 1 disables the Completer Abort Error status reporting
  [3] CPLTOM — When set to 1 disables the Completion Timeout status reporting
  [2] FCPROERM — When set to 1 disables the Flow Control Protocol Error status reporting
  [1] POTLRCVM — When set to 1 disables the Poisoned TLP received status reporting
  [0] DLPROTM — When set to 1 disables the Data Link Layer Protocol Error status reporting
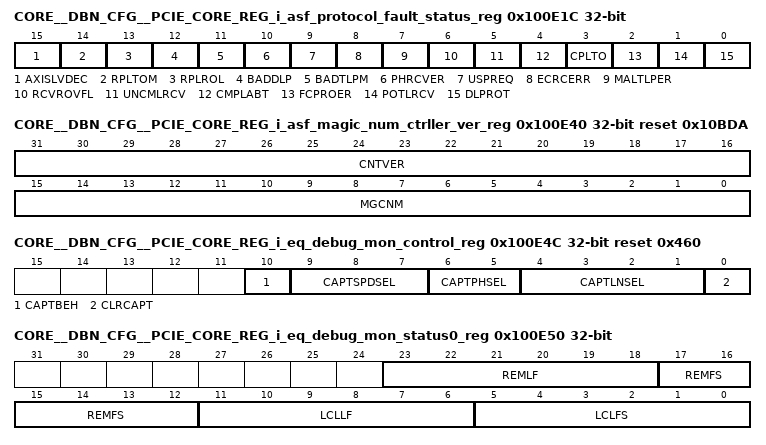
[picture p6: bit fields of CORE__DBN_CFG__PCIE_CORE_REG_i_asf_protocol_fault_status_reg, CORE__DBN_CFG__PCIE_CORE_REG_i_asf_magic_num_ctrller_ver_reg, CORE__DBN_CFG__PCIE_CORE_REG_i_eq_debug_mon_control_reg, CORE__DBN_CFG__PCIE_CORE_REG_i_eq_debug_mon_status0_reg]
0x100E1C CORE__DBN_CFG__PCIE_CORE_REG_i_asf_protocol_fault_status_reg access not given — This status register holds the different protocol errors observed by the IP. This error is logged into this register if the corresponding bit in the ASF Protocol Fault Mask Register is not masked.
  [15] AXISLVDEC — This bit is set when the AXI interface sends SLVERR or DECERR to the user (access R/W1TC)
  [14] RPLTOM — This bit is set when the replay timer in the Data Link Layer of the Controller times out. (access R/W1TC)
  [13] RPLROL — This bit is set when the replay count rolls over after three re transmissions of a TLP at the Data Link Layer of the Controller. (access R/W1TC)
  [12] BADDLP — This bit is set when an LCRC error is detected in a received DLLP (access R/W1TC)
  [11] BADTLPM — This bit is set when an error is detected in a received TLP by the Data Link Layer of the Controller. (access R/W1TC)
  [10] PHRCVER — This bit is set when an error is detected in the receive side of the Physical Layer of the Controller (access R/W1TC)
  [9] USPREQ — This bit is set when the Controller has received a request from the link that it does not support. (access R/W1TC)
  [8] ECRCERR — This bit is set when the Controller has detected an ECRC error in a received TLP (access R/W1TC)
  [7] MALTLPER — This bit is set when the Controller receives a malformed TLP from the link. (access R/W1TC)
  [6] RCVROVFL — This bit is set when the Controller receives a TLP in violation of the receive credit currently available. (access R/W1TC)
  [5] UNCMLRCV — This bit is set when the Controller has received an unexpected Completion packet from the link (access R/W1TC)
  [4] CMPLABT — This bit is set when the Controller has returned the Completer Abort [CA] status to a request received from the link. (access R/W1TC)
  [3] CPLTO — This bit is set when the completion timer associated with an outstanding request times out. (access R/W1TC)
  [2] FCPROER — This bit is set when certain violations of the flow control protocol are detected by the Controller. (access R/W1TC)
  [1] POTLRCV — This bit is set when the Controller receives a poisoned TLP from the link. (access R/W1TC)
  [0] DLPROT — This bit is set when the Controller receives an Ack or Nak DLLP whose sequence number does not correspond to that of an unacknowledged TLP or that of the last acknowledged TLP (access R/W1TC)
0x100E40 CORE__DBN_CFG__PCIE_CORE_REG_i_asf_magic_num_ctrller_ver_reg ro reset 0x10BDA — This register contains two read only 16 bit hardcoded values used by the software.
  [31:16] CNTVER — This 16bit value is used to determine the revision number of the controller by the software
  [15:0] MGCNM — This 16bit value is used for verification of base address by the software
0x100E4C CORE__DBN_CFG__PCIE_CORE_REG_i_eq_debug_mon_control_reg access per field reset 0x460 — The register bits to Control EQ debug Monitor operation are implemented in this Register.
  [10] CAPTBEH ro — If this is set , the first 64 equalization info events are captured else the last 64 events are captured
  [9:7] CAPTSPDSEL rw — Selects the Link Speed at which capture is to be done 000 : Any speed, 001 : Gen 3, 010 : Gen 4, 100 : Gen 5
  [6:5] CAPTPHSEL rw — Selects the Equalization Phase when capture is to be done 01 : Phase 2, 10 : Phase 3, 11 : Phase 2 and 3
  [4:1] CAPTLNSEL rw — Selects the Lane whose Equalization Debug information is to be captured.Please note,this signifies the physical lane number.
  [0] CLRCAPT rw — Setting this bit clears all captured information in the EQ Debug Status Registers. If it is unset then capture is allowed in status registers.
0x100E50 CORE__DBN_CFG__PCIE_CORE_REG_i_eq_debug_mon_status0_reg ro — Both the Local and Remote EQ FS and LF values are captured in this Register.
  [23:18] REMLF — Remote PHY's LF Value Of the Lane and Speed Selected.
  [17:12] REMFS — Remote PHY's FS Value Of the Lane and Speed Selected.
  [11:6] LCLLF — Local PHY's LF Value Of the Lane and Speed Selected.
  [5:0] LCLFS — Local PHY's FS Value Of the Lane and Speed Selected.
